# STM32U083xx register map
File version: 1.0
Registers are 32-bit, read-write, reset 0x0 unless marked. A register's access mark holds for its fields unless they carry their own. Offsets are from the block's base; [hi:lo] are bit positions.

## I2C1 — Inter-integrated Circuit Interface
Base 0x40005400
Same registers: I2C3 0x40008800
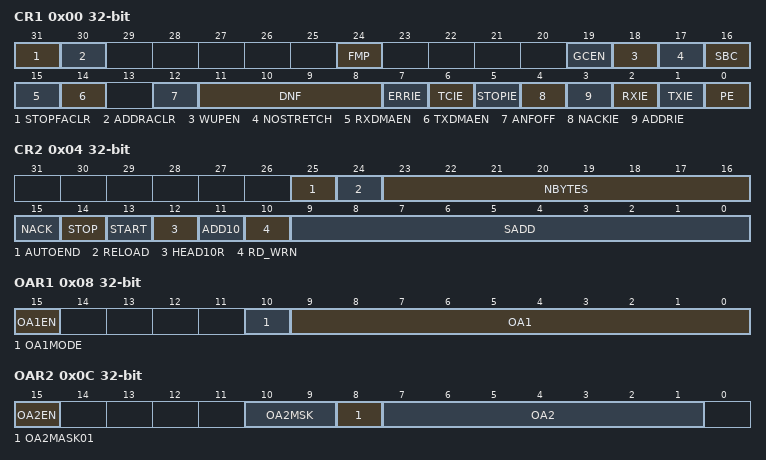
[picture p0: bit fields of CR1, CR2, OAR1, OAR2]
0x00 CR1 — I2C Control register 1
  [31] STOPFACLR — STOPFACLR enable
  [30] ADDRACLR — ADDRACLR enable
  [24] FMP — Fast-mode Plus 20 mA drive enable
  [19] GCEN — General call enable
  [18] WUPEN — Wakeup from STOP enable
  [17] NOSTRETCH — Clock stretching disable
  [16] SBC — Slave byte control
  [15] RXDMAEN — DMA reception requests enable
  [14] TXDMAEN — DMA transmission requests enable
  [12] ANFOFF — Analog noise filter OFF
  [11:8] DNF — Digital noise filter
  [7] ERRIE — Errors interrupt enable
  [6] TCIE — Transfer complete interrupt enable
  [5] STOPIE — STOP detection interrupt enable
  [4] NACKIE — NACK received interrupt enable
  [3] ADDRIE — Address match interrupt enable
  [2] RXIE — RX interrupt enable
  [1] TXIE — TX interrupt enable
  [0] PE — Peripheral enable
0x04 CR2 — I2C Control register 2
  [25] AUTOEND — Automatic end mode (master mode)
  [24] RELOAD — NBYTES reload mode
  [23:16] NBYTES — Number of bytes
  [15] NACK — NACK generation (slave mode)
    0=ACK (ACK is sent after current received byte.); 1=NACK (NACK is sent after current received byte.)
  [14] STOP — STOP generation (master mode)
  [13] START — START generation
  [12] HEAD10R — 10-bit address header only read direction (master mode)
  [11] ADD10 — 10-bit addressing mode (master mode)
    0=MODE_7BIT (Master operates in 7-bit addressing mode.); 1=MODE_10BIT (Master operates in 10-bit addressing mode.)
  [10] RD_WRN — Transfer direction (master mode)
    0=WRITE (Master request a write transfer.); 1=READ (Master request a read transfer.)
  [9:0] SADD — Slave address (master mode)
0x08 OAR1 — I2C Own address 1 register
  [15] OA1EN — Own address 1 enable
  [10] OA1MODE — Own address 1 10-bit mode
  [9:0] OA1 — Interface own address 1
0x0C OAR2 — I2C Own address 2 register
  [15] OA2EN — Own address 2 enable
  [10:9] OA2MSK — Own address 2 masks
  [8] OA2MASK01 — OA2[1] is masked, Only OA2[7:2] are compared
  [7:1] OA2 — Interface own address 2
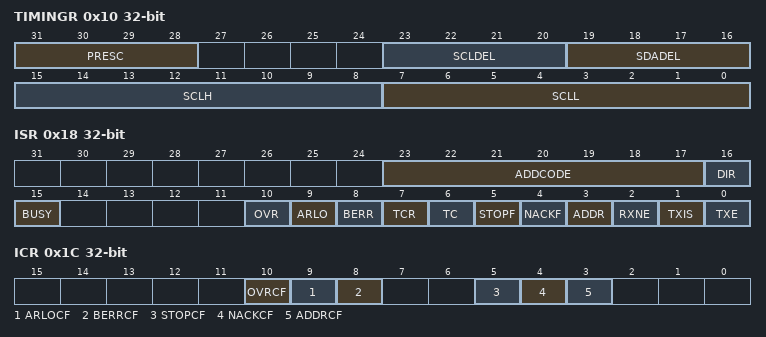
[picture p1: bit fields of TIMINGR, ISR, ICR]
0x10 TIMINGR — I2C Timing register
  [31:28] PRESC — Timings prescaler
  [23:20] SCLDEL — Data setup time
  [19:16] SDADEL — Data hold time
  [15:8] SCLH — SCL high period (master mode)
  [7:0] SCLL — SCL low period (master mode)
0x18 ISR — I2C Interrupt and status register
  [23:17] ADDCODE — Address match code (slave mode)
  [16] DIR — Transfer direction (slave mode)
    0=WRITE; 1=READ
  [15] BUSY — Bus busy
  [10] OVR — Overrun/Underrun
  [9] ARLO — Arbitration lost
  [8] BERR — Bus error
  [7] TCR — Transfer complete reload
  [6] TC — Transfer complete (master mode)
  [5] STOPF — STOP detection flag
  [4] NACKF — NACK received flag
  [3] ADDR — Address matched (slave mode)
  [2] RXNE — Receive data register not empty
  [1] TXIS — Transmit interrupt status
  [0] TXE — Transmit data register empty
0x1C ICR — I2C Interrupt clear register
  [10] OVRCF — Overrun/Underrun clear flag
  [9] ARLOCF — Arbitration lost clear flag
  [8] BERRCF — Bus error clear flag
  [5] STOPCF — STOP detection clear flag
  [4] NACKCF — NACK clear flag
  [3] ADDRCF — Address matched clear flag
0x24 RXDR — I2C Receive data register
  [7:0] RXDATA — 8-bit receive data
0x28 TXDR — I2C Transmit data register
  [7:0] TXDATA — 8-bit transmit data

## I2C2 — Inter-integrated Circuit Interface
Base 0x40005800
Same registers: I2C4 0x4000A000
Registers as I2C1; these are added or differ:
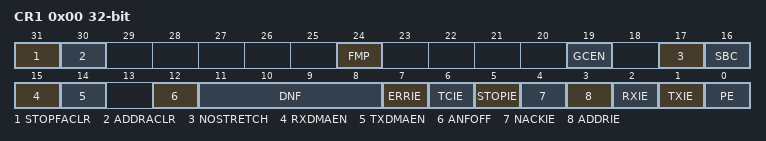
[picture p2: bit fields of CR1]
0x00 CR1 — I2C Control register 1
  [31] STOPFACLR — STOPFACLR enable
  [30] ADDRACLR — ADDRACLR enable
  [24] FMP — Fast-mode Plus 20 mA drive enable
  [19] GCEN — General call enable
  [17] NOSTRETCH — Clock stretching disable
  [16] SBC — Slave byte control
  [15] RXDMAEN — DMA reception requests enable
  [14] TXDMAEN — DMA transmission requests enable
  [12] ANFOFF — Analog noise filter OFF
  [11:8] DNF — Digital noise filter
  [7] ERRIE — Errors interrupt enable
  [6] TCIE — Transfer complete interrupt enable
  [5] STOPIE — STOP detection interrupt enable
  [4] NACKIE — NACK received interrupt enable
  [3] ADDRIE — Address match interrupt enable
  [2] RXIE — RX interrupt enable
  [1] TXIE — TX interrupt enable
  [0] PE — Peripheral enable
